# psoc4100sp256kb register map
Vendor: Infineon Technologies; Series: PSOC4100Sp256KB; File version: 1.0
CPU: CM0PLUS r0p1, little endian, MPU, no FPU, VTOR, 2 interrupt priority bits, 29 interrupts
Registers are 32-bit, read-write, reset 0x0 unless marked. A register's access mark holds for its fields unless they carry their own. Offsets are from the block's base; [hi:lo] are bit positions; lines under a group give offsets from that group; {n}, {i} and the like mark numbered series; 'fields as' and 'values as' point back to an identical list; <NAME> marks a mode.

## LPCOMP — Low Power Comparators
Base 0x402B0000
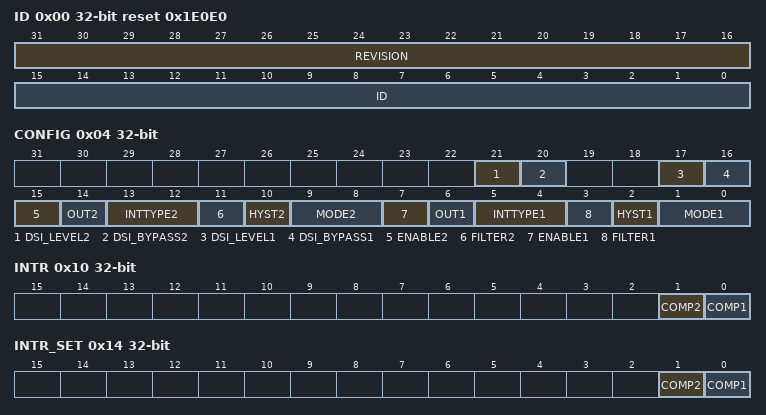
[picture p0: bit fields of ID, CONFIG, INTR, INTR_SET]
0x00 ID ro reset 0x1E0E0 — ID & Revision
  [31:16] REVISION — the version number is 0x0001
  [15:0] ID — the ID of LPCOMP peripheral is 0xE0E0
0x04 CONFIG — LPCOMP Configuration Register
  [21] DSI_LEVEL2 — Opamp2 comparator DSI (trigger) out level : 0=pulse, 1=level
  [20] DSI_BYPASS2 — Opamp2 bypass comparator output synchronization for DSI output: 0=synchronize (level or pulse), 1=bypass (output async) Note that in DeepSleep mode this bit needs to be set to observe the DSI output on the dedicated pin.
  [17] DSI_LEVEL1 — Opamp1 comparator DSI (trigger) out level : 0=pulse, 1=level
  [16] DSI_BYPASS1 — Opamp1 bypass comparator output synchronization for DSI output: 0=synchronize (level or pulse), 1=bypass (output async) Note that in DeepSleep mode this bit needs to be set to observe the DSI output on the dedicated pin.
  [15] ENABLE2 — Enable comparator #2
  [14] OUT2 ro — Current output value of the comparator.
  [13:12] INTTYPE2 — Sets which edge will trigger an IRQ
    0=DISABLE (Disabled, no interrupts will be detected); 1=RISING (Rising edge); 2=FALLING (Falling edge); 3=BOTH (Both rising and falling edges)
  [11] FILTER2
  [10] HYST2 — Add 10mV hysteresis to the comparator - 0: Enable Hysteresis - 1: Disable Hysteresis
  [9:8] MODE2 — Operating mode for the comparator
    0=SLOW (Slow operating mode (uses less power, <50uA)); 1=FAST (Fast operating mode (uses more power, <400uA)); 2=ULP (Ultra low power operting mode (uses ~2-4uA))
  [7] ENABLE1 — Enable comparator #1
  [6] OUT1 ro — Current output value of the comparator.
  [5:4] INTTYPE1 — Sets which edge will trigger an IRQ
    values as INTTYPE2
  [3] FILTER1
  [2] HYST1 — Add 10mV hysteresis to the comparator - 0: Enable Hysteresis - 1: Disable Hysteresis
  [1:0] MODE1 — Operating mode for the comparator
    values as MODE2
0x10 INTR — LPCOMP Interrupt request register
  [1] COMP2 write-1-clears — Comparator 2 Interrupt: hardware sets this interrupt when comparator 0 triggers. Write with '1' to clear bit.
  [0] COMP1 write-1-clears — Comparator 1 Interrupt: hardware sets this interrupt when comparator 0 triggers. Write with '1' to clear bit.
0x14 INTR_SET — LPCOMP Interrupt set register
  [1] COMP2 write-1-sets — Write with '1' to set corresponding bit in interrupt request register.
  [0] COMP1 write-1-sets — Write with '1' to set corresponding bit in interrupt request register.
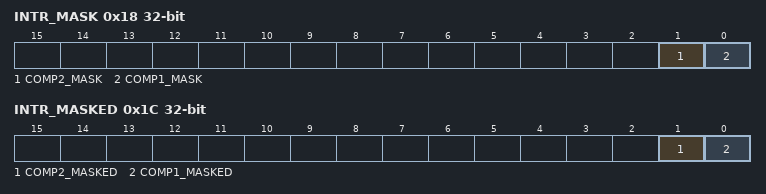
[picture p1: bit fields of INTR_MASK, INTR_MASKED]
0x18 INTR_MASK — LPCOMP Interrupt request mask
  [1] COMP2_MASK — Mask bit for corresponding bit in interrupt request register.
  [0] COMP1_MASK — Mask bit for corresponding bit in interrupt request register.
0x1C INTR_MASKED ro — LPCOMP Interrupt request masked
  [1] COMP2_MASKED — Logical and of corresponding request and mask bits.
  [0] COMP1_MASKED — Logical and of corresponding request and mask bits.
0xFF00 TRIM1 — LPCOMP Trim Register
  [4:0] COMP1_TRIMA — Trim A for Comparator #1
0xFF04 TRIM2 — LPCOMP Trim Register
  [4:0] COMP1_TRIMB — Trim B for Comparator #1
0xFF08 TRIM3 — LPCOMP Trim Register
  [4:0] COMP2_TRIMA — Trim A for Comparator #2
0xFF0C TRIM4 — LPCOMP Trim Register
  [4:0] COMP2_TRIMB — Trim B for Comparator #2

## PASS0 — PASS top-level MMIO (DSABv2, INTR)
Base 0x403F0000
Same registers: PASS1 0x404F0000
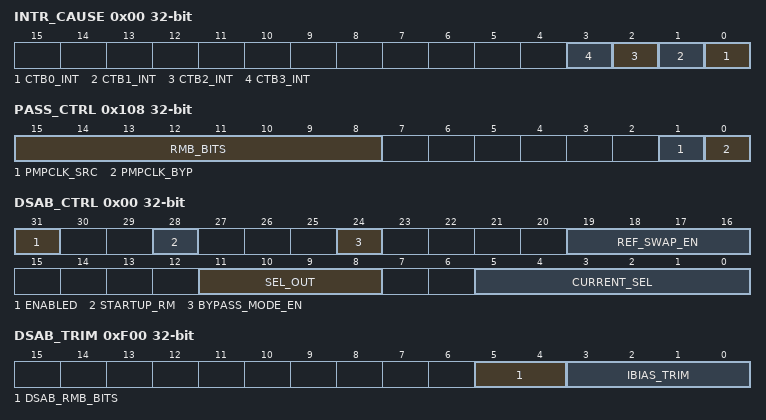
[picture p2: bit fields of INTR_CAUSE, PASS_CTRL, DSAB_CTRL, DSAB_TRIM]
0x00 INTR_CAUSE ro — Interrupt cause register
  [n] CTB{n}_INT (n=0..3) — CTB{n} interrupt pending
0x30 DFT_CTRL — DFT control register
  [0] DSAB_ADFT_RES_EN — Close the switch to connect the DSAB ADFT resistor to the AMUXBUS
0x108 PASS_CTRL — PASS Control
  [15:8] RMB_BITS — Risk mitigation bits
  [1] PMPCLK_SRC — - 0: Pump clk is clk_hf - 1: Pump clk is direct from SRSS
  [0] PMPCLK_BYP — - 0: Pump clk is clk_hf/2 - 1: Pump clk is selected from PMPCLK_SRC
0xE00 DSAB group — DSAB configuration
  0x00 DSAB_CTRL — global DSAB control
    [31] ENABLED — This field (along with SEL_OUT and REF_SWAP_EN) provides bitwise selection of the current sources that drive the DSAB ZTC and PTAT outputs. See SEL_OUT field for truth tables. In SRSSLT devices, in active mode, this bit is overridden to '1', that is - it is always enabled in active mode.
    [28] STARTUP_RM — Risk mitigation control 1 - Force start the startup circuit
    [24] BYPASS_MODE_EN — 0 - DSAB PTAT generator is powered from DSAB regulator: VDDA must be at least 2.4V 1 - DSAB PTAT generator is pwoered directly from VDDA: VDDA cannot exceed 4.0V
    [19:16] REF_SWAP_EN — This field (along with SEL_OUT and ENABLED) provides bitwise selection of the current sources that drive the DSAB ZTC and PTAT outputs. See SEL_OUT field for truth tables.
    [11:8] SEL_OUT
    [5:0] CURRENT_SEL — DSAB DAC control field Nominal DSAB Output Current = CURRENT_SEL * 0.075 uA In products with SRSS-LITE, this setting impacts the CTB(m) offset. A value of 0x20 is used during factory trim and is required to maintain low offsets across temperature variation. If a different setting is used then a periodic re-trim of CTB(m) offset should be performed.
  0x04 DSAB_DFT — DFT bits
    [3:0] EN_DFT — - 0: DSAB DFT disabled - 1: DSAB DFT enabled (connect output to amuxbus) 0001 - PTAT<0> 0010 - PTAT<1> 0011 - PTAT<1:0> 0100 - PTAT<2> 0111 - PTAT<2:0> 1000 - PTAT<3> 1111 - PTAT<3:0> 1001 - DSAB Reg Out
0xF00 DSAB_TRIM — DSAB Trim bits
  [5:4] DSAB_RMB_BITS — Risk mitigation bits
  [3:0] IBIAS_TRIM — 1111=lowest, 0000=highest
